VERSION "dbc-export 1 2026.26.6.5"

NS_ :

BS_:

BU_: APB APP APS DAS DPB EPAS3S EPASTS ESP GTW IBST IDB PARK RADC RCM RCM2 RCM3 RCU TPMS TRCM USM

BO_ 991 UI_status2: 8 GTW
 SG_ UI_mobileAppStepCount : 0|16@1+ (1,0) [0|65535] "" Vector__XXX
 SG_ UI_userRequestSnapshot : 16|1@1+ (1,0) [0|1] "" Vector__XXX
 SG_ UI_touchDetected : 17|1@1+ (1,0) [0|1] "" Vector__XXX
 SG_ UI_validDeviceForEUSummon : 18|1@1+ (1,0) [0|1] "" Vector__XXX
 SG_ UI_locatedAtHome : 19|1@1+ (1,0) [0|1] "" Vector__XXX
 SG_ UI_locatedAtWork : 20|1@1+ (1,0) [0|1] "" Vector__XXX
 SG_ UI_locatedAtFavorite : 21|1@1+ (1,0) [0|1] "" Vector__XXX
 SG_ UI_displayInDarkMode : 22|1@1+ (1,0) [0|1] "" Vector__XXX
 SG_ UI_userActivity : 23|1@1+ (1,0) [0|1] "" Vector__XXX
 SG_ UI_activeTouchPoints : 24|8@1+ (1,0) [0|255] "1" Vector__XXX
 SG_ UI_linkState : 32|2@1+ (1,0) [0|3] "" Vector__XXX
 SG_ UI_sentryModeState : 34|3@1+ (1,0) [0|7] "" Vector__XXX
 SG_ UI_autopilotSentryRequest : 37|1@1+ (1,0) [0|1] "" Vector__XXX
 SG_ UI_mobileAppConnected : 38|1@1+ (1,0) [0|1] "" Vector__XXX
 SG_ UI_phoneLeftInCabin : 39|1@1+ (1,0) [0|1] "" Vector__XXX
 SG_ UI_autoshiftDRState : 40|3@1+ (1,0) [0|7] "" Vector__XXX
 SG_ UI_wifiBtModuleType : 43|3@1+ (1,0) [0|7] "" Vector__XXX
 SG_ UI_sohHealthStatus : 46|2@1+ (1,0) [0|3] "" Vector__XXX
 SG_ UI_selfParkState : 48|8@1+ (1,0) [0|254] "" Vector__XXX
 SG_ UI_summonDeviceIndex : 56|2@1+ (1,0) [0|3] "" Vector__XXX
 SG_ UI_fullScreenMode : 58|1@1+ (1,0) [0|1] "" Vector__XXX
 SG_ UI_sentryModeCameraDetection : 59|1@1+ (1,0) [0|1] "" Vector__XXX
 SG_ UI_wakeOnIPActive : 60|1@1+ (1,0) [0|1] "" Vector__XXX
 SG_ UI_sapActive : 61|1@1+ (1,0) [0|1] "" Vector__XXX
 SG_ UI_sapClients : 62|1@1+ (1,0) [0|1] "" Vector__XXX
 SG_ UI_connectivityStandbyActive : 63|1@1+ (1,0) [0|1] "" Vector__XXX

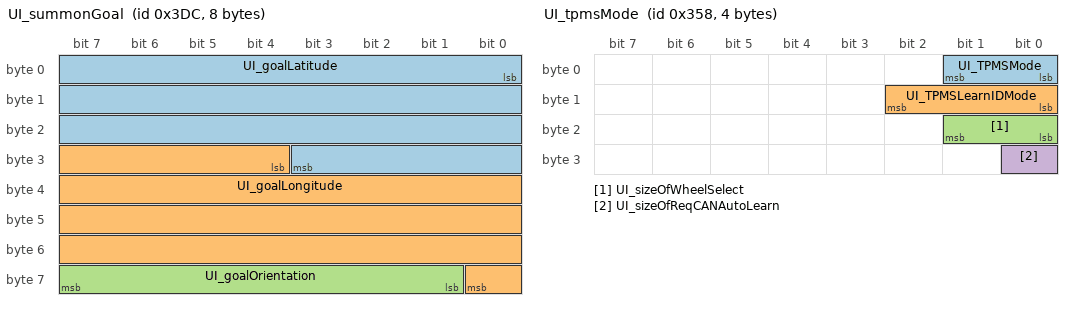
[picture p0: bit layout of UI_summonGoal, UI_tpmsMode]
BO_ 988 UI_summonGoal: 8 GTW
 SG_ UI_goalLatitude : 0|28@1- (1.0e-06,0) [-134.217728|134.217727] "deg" Vector__XXX
 SG_ UI_goalLongitude : 28|29@1- (1.0e-06,0) [-268.435456|268.435455] "deg" Vector__XXX
 SG_ UI_goalOrientation : 57|7@1+ (2.8125,0) [0|357.1875] "deg" Vector__XXX

BO_ 1064 UI_telemetryControl: 8 GTW
 SG_ UI_TCR_enable : 0|1@1+ (1,0) [0|1] "" Vector__XXX
 SG_ UI_TCR_moveStateStanding : 1|1@1+ (1,0) [0|1] "" Vector__XXX
 SG_ UI_TCR_moveStateStopped : 2|1@1+ (1,0) [0|1] "" Vector__XXX
 SG_ UI_TCR_moveStateMoving : 3|1@1+ (1,0) [0|1] "" Vector__XXX
 SG_ UI_TCR_moveStateIndeterm : 4|1@1+ (1,0) [0|1] "" Vector__XXX
 SG_ UI_TCR_classConstElem : 5|1@1+ (1,0) [0|1] "" Vector__XXX
 SG_ UI_TCR_classMovingPed : 6|1@1+ (1,0) [0|1] "" Vector__XXX
 SG_ UI_TCR_classMovingTwoWheel : 7|1@1+ (1,0) [0|1] "" Vector__XXX
 SG_ UI_TCR_classMovingFourWheel : 8|1@1+ (1,0) [0|1] "" Vector__XXX
 SG_ UI_TCR_classUnknown : 9|1@1+ (1,0) [0|1] "" Vector__XXX
 SG_ UI_TCR_downSampleFactor : 10|4@1+ (1,0) [0|15] "" Vector__XXX
 SG_ UI_TCR_wExist : 24|5@1+ (1,0) [0|31] "" Vector__XXX
 SG_ UI_TCR_vehSpeed : 32|8@1+ (1,0) [0|255] "" Vector__XXX
 SG_ UI_TCR_minRCS : 40|8@1+ (0.25,-14) [-14|49.75] "dB" Vector__XXX
 SG_ UI_TCR_maxDy : 48|5@1+ (0.5,0) [0|15.5] "m" Vector__XXX
 SG_ UI_TCR_maxObjects : 56|5@1+ (1,0) [0|31] "" Vector__XXX
 SG_ UI_TCR_maxRoadClass : 61|3@1+ (1,0) [0|7] "" Vector__XXX

BO_ 856 UI_tpmsMode: 4 GTW
 SG_ UI_TPMSMode : 0|2@1+ (1,0) [0|3] "" Vector__XXX
 SG_ UI_TPMSLearnIDMode : 8|3@1+ (1,0) [0|7] "" Vector__XXX
 SG_ UI_sizeOfWheelSelect : 16|2@1+ (1,0) [0|3] "" Vector__XXX
 SG_ UI_sizeOfReqCANAutoLearn : 24|1@1+ (1,0) [0|1] "" Vector__XXX

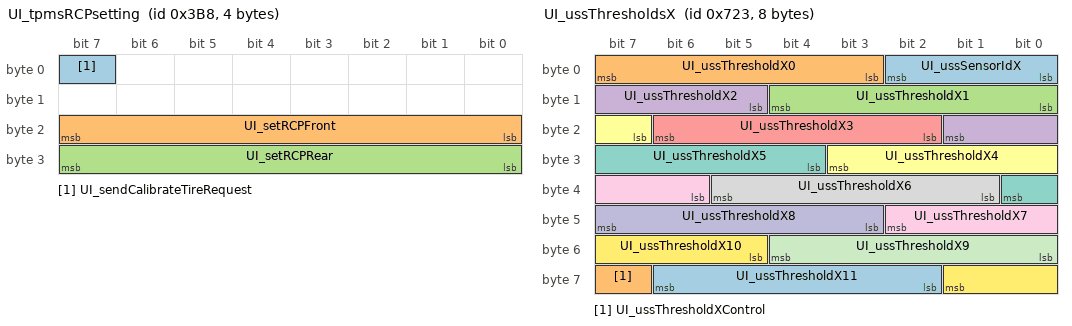
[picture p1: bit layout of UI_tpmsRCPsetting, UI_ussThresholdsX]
BO_ 952 UI_tpmsRCPsetting: 4 GTW
 SG_ UI_sendCalibrateTireRequest : 7|1@1+ (1,0) [0|1] "" Vector__XXX
 SG_ UI_setRCPFront : 16|8@1+ (0.025,0) [0|6.375] "bar" Vector__XXX
 SG_ UI_setRCPRear : 24|8@1+ (0.025,0) [0|6.375] "bar" Vector__XXX

BO_ 852 UI_uiHealthStatus: 6 GTW
 SG_ UI_centerDisplayRunning : 0|1@1+ (1,0) [0|1] "" Vector__XXX
 SG_ UI_centerDisplaySM : 1|3@1+ (1,0) [0|7] "" Vector__XXX
 SG_ UI_centerDisplayPowerOn : 4|1@1+ (1,0) [0|1] "" Vector__XXX
 SG_ UI_centerDisplayCrtcOk : 5|1@1+ (1,0) [0|1] "" Vector__XXX
 SG_ UI_centerDisplayHardwareOk : 6|1@1+ (1,0) [0|1] "" Vector__XXX
 SG_ UI_centerDisplayWindowManagerOk : 7|1@1+ (1,0) [0|1] "" Vector__XXX
 SG_ UI_centerDisplayCompositorOk : 8|1@1+ (1,0) [0|1] "" Vector__XXX
 SG_ UI_apVisualizationOk : 9|1@1+ (1,0) [0|1] "" Vector__XXX
 SG_ UI_autonomyCenterDispStatus : 10|2@1+ (1,0) [1|3] "" Vector__XXX
 SG_ UI_autonomyRearDispStatus : 12|2@1+ (1,0) [1|3] "" Vector__XXX
 SG_ UI_autonomyConnectivityStatus : 14|2@1+ (1,0) [1|3] "" Vector__XXX
 SG_ UI_autonomyConnectivtyHWOk : 16|1@1+ (1,0) [0|1] "" Vector__XXX
 SG_ UI_autonomyQtCarStatus : 17|2@1+ (1,0) [1|3] "" Vector__XXX
 SG_ UI_autonomyQtCarRearStatus : 19|2@1+ (1,0) [1|3] "" Vector__XXX
 SG_ UI_autonomyDASServerStatus : 21|2@1+ (1,0) [1|3] "" Vector__XXX
 SG_ UI_rearDisplayRunning : 23|1@1+ (1,0) [0|1] "" Vector__XXX
 SG_ UI_rearDisplayPowerOn : 24|1@1+ (1,0) [0|1] "" Vector__XXX
 SG_ UI_rearDisplaySM : 25|3@1+ (1,0) [0|7] "" Vector__XXX
 SG_ UI_rearDisplayCrtcOk : 28|1@1+ (1,0) [0|1] "" Vector__XXX
 SG_ UI_rearDisplayHardwareOk : 29|1@1+ (1,0) [0|1] "" Vector__XXX
 SG_ UI_rearDisplayWindowManagerOk : 30|1@1+ (1,0) [0|1] "" Vector__XXX
 SG_ UI_rearDisplayCompositorOk : 31|1@1+ (1,0) [0|1] "" Vector__XXX

BO_ 1827 UI_ussThresholdsX: 8 GTW
 SG_ UI_ussSensorIdX : 0|3@1+ (1,0) [0|7] "" Vector__XXX
 SG_ UI_ussThresholdX0 : 3|5@1+ (1,0) [0|31] "" Vector__XXX
 SG_ UI_ussThresholdX1 : 8|5@1+ (1,0) [0|31] "" Vector__XXX
 SG_ UI_ussThresholdX2 : 13|5@1+ (1,0) [0|31] "" Vector__XXX
 SG_ UI_ussThresholdX3 : 18|5@1+ (1,0) [0|31] "" Vector__XXX
 SG_ UI_ussThresholdX4 : 23|5@1+ (1,0) [0|31] "" Vector__XXX
 SG_ UI_ussThresholdX5 : 28|5@1+ (1,0) [0|31] "" Vector__XXX
 SG_ UI_ussThresholdX6 : 33|5@1+ (1,0) [0|31] "" Vector__XXX
 SG_ UI_ussThresholdX7 : 38|5@1+ (1,0) [0|31] "" Vector__XXX
 SG_ UI_ussThresholdX8 : 43|5@1+ (1,0) [0|31] "" Vector__XXX
 SG_ UI_ussThresholdX9 : 48|5@1+ (1,0) [0|31] "" Vector__XXX
 SG_ UI_ussThresholdX10 : 53|5@1+ (1,0) [0|31] "" Vector__XXX
 SG_ UI_ussThresholdX11 : 58|5@1+ (1,0) [0|31] "" Vector__XXX
 SG_ UI_ussThresholdXControl : 63|1@1+ (1,0) [0|1] "" Vector__XXX

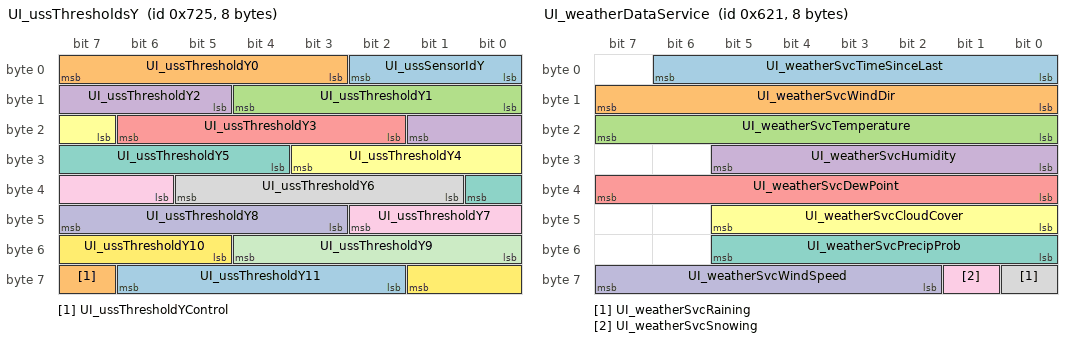
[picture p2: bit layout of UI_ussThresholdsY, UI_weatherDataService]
BO_ 1829 UI_ussThresholdsY: 8 GTW
 SG_ UI_ussSensorIdY : 0|3@1+ (1,0) [0|7] "" Vector__XXX
 SG_ UI_ussThresholdY0 : 3|5@1+ (1,0) [0|31] "" Vector__XXX
 SG_ UI_ussThresholdY1 : 8|5@1+ (1,0) [0|31] "" Vector__XXX
 SG_ UI_ussThresholdY2 : 13|5@1+ (1,0) [0|31] "" Vector__XXX
 SG_ UI_ussThresholdY3 : 18|5@1+ (1,0) [0|31] "" Vector__XXX
 SG_ UI_ussThresholdY4 : 23|5@1+ (1,0) [0|31] "" Vector__XXX
 SG_ UI_ussThresholdY5 : 28|5@1+ (1,0) [0|31] "" Vector__XXX
 SG_ UI_ussThresholdY6 : 33|5@1+ (1,0) [0|31] "" Vector__XXX
 SG_ UI_ussThresholdY7 : 38|5@1+ (1,0) [0|31] "" Vector__XXX
 SG_ UI_ussThresholdY8 : 43|5@1+ (1,0) [0|31] "" Vector__XXX
 SG_ UI_ussThresholdY9 : 48|5@1+ (1,0) [0|31] "" Vector__XXX
 SG_ UI_ussThresholdY10 : 53|5@1+ (1,0) [0|31] "" Vector__XXX
 SG_ UI_ussThresholdY11 : 58|5@1+ (1,0) [0|31] "" Vector__XXX
 SG_ UI_ussThresholdYControl : 63|1@1+ (1,0) [0|1] "" Vector__XXX

BO_ 947 UI_vehicleControl2: 8 GTW
 SG_ UI_gloveboxRequest : 0|1@1+ (1,0) [0|1] "" Vector__XXX
 SG_ UI_trunkRequest : 1|1@1+ (1,0) [0|1] "" Vector__XXX
 SG_ UI_UMCUpdateInhibit : 2|1@1+ (1,0) [0|1] "" Vector__XXX
 SG_ UI_WCUpdateInhibit : 3|1@1+ (1,0) [0|1] "" Vector__XXX
 SG_ UI_soundHornOnLock : 4|1@1+ (1,0) [0|1] "" Vector__XXX
 SG_ UI_locksPanelActive : 5|1@1+ (1,0) [0|1] "" Vector__XXX
 SG_ UI_PINToDriveEnabled : 6|1@1+ (1,0) [0|1] "" Vector__XXX
 SG_ UI_PINToDrivePassed : 7|1@1+ (1,0) [0|1] "" Vector__XXX
 SG_ UI_disableMirrorAutoDim : 8|1@1+ (1,0) [0|1] "" Vector__XXX
 SG_ UI_lightSwitch : 9|3@1+ (1,0) [0|7] "" Vector__XXX
 SG_ UI_readyToAddKey : 12|1@1+ (1,0) [0|1] "" Vector__XXX
 SG_ UI_alarmTriggerRequest : 13|1@1+ (1,0) [0|1] "" Vector__XXX
 SG_ UI_VCSECFeature1 : 14|1@1+ (1,0) [0|1] "" Vector__XXX
 SG_ UI_VCLEFTFeature1 : 15|1@1+ (1,0) [0|1] "" Vector__XXX
 SG_ UI_summonState : 16|2@1+ (1,0) [1|3] "" Vector__XXX
 SG_ UI_displayOnForUser : 18|1@1+ (1,0) [0|1] "" Vector__XXX
 SG_ UI_freeRollModeRequest : 19|1@1+ (1,0) [0|1] "" Vector__XXX
 SG_ UI_BLEPushNotificationRequest : 20|1@1+ (1,0) [0|1] "" Vector__XXX
 SG_ UI_pairKeyQRCodeDisplaying : 21|1@1+ (1,0) [0|1] "" Vector__XXX
 SG_ UI_keepAutopilotAwake : 22|1@1+ (1,0) [0|1] "" Vector__XXX
 SG_ UI_batteryPreconditioningRequest : 23|1@1+ (1,0) [0|1] "" Vector__XXX
 SG_ UI_coastDownMode : 24|1@1+ (1,0) [0|1] "" Vector__XXX
 SG_ UI_autopilotPowerStateRequest : 25|2@1+ (1,0) [0|3] "" Vector__XXX
 SG_ UI_shorted12VCellTestMode : 27|2@1+ (1,0) [0|3] "" Vector__XXX
 SG_ UI_autoRollWindowsOnLockEnable : 29|1@1+ (1,0) [0|1] "" Vector__XXX
 SG_ UI_virtualPitchSensorOverrideOKF : 30|1@1+ (1,0) [0|1] "" Vector__XXX
 SG_ UI_conditionalLoggingEnabledVCSE : 31|1@1+ (1,0) [0|1] "" Vector__XXX
 SG_ UI_WC3UpdateInhibit : 32|1@1+ (1,0) [0|1] "" Vector__XXX
 SG_ UI_steeringWheelHeatReq : 33|1@1+ (1,0) [0|1] "" Vector__XXX
 SG_ UI_disableHorn : 34|1@1+ (1,0) [0|1] "" Vector__XXX
 SG_ UI_frontLeftSeatFanReq : 37|2@1+ (1,0) [0|3] "" Vector__XXX
 SG_ UI_frontRightSeatAutoClimateReq : 39|1@1+ (1,0) [0|1] "" Vector__XXX
 SG_ UI_frontRightSeatFanReq : 40|2@1+ (1,0) [0|3] "" Vector__XXX
 SG_ UI_3RLeftSeatHeatReq : 44|2@1+ (1,0) [0|3] "" Vector__XXX
 SG_ UI_3RRightSeatHeatReq : 46|2@1+ (1,0) [0|3] "" Vector__XXX
 SG_ UI_sleepFeature1 : 51|1@1+ (1,0) [0|1] "" Vector__XXX
 SG_ UI_dcr12VThreshold : 52|4@1+ (1,0) [0|15] "" Vector__XXX
 SG_ UI_frontLeftSeatAutoClimateReq : 56|1@1+ (1,0) [0|1] "" Vector__XXX
 SG_ UI_wiperHeaterReq : 57|1@1+ (1,0) [0|1] "" Vector__XXX
 SG_ UI_tireSeason : 59|1@1+ (1,0) [0|1] "" Vector__XXX
 SG_ UI_saveTireConfigReq : 60|1@1+ (1,0) [0|1] "" Vector__XXX
 SG_ UI_silentAlarm : 61|1@1+ (1,0) [0|1] "" Vector__XXX
 SG_ UI_sleepFeature2 : 63|1@1+ (1,0) [0|1] "" Vector__XXX

BO_ 644 UI_vehicleModes: 8 GTW
 SG_ UI_factoryMode : 0|1@1+ (1,0) [0|1] "" Vector__XXX
 SG_ UI_transportMode : 1|1@1+ (1,0) [0|1] "" Vector__XXX
 SG_ UI_showroomMode : 2|1@1+ (1,0) [0|1] "" Vector__XXX
 SG_ UI_serviceMode : 3|1@1+ (1,0) [0|1] "" Vector__XXX
 SG_ UI_isDelivered : 4|1@1+ (1,0) [0|1] "" Vector__XXX
 SG_ UI_hasEverBeenDelivered : 5|1@1+ (1,0) [0|1] "" Vector__XXX
 SG_ UI_homelinkV2Command0 : 8|8@1+ (1,0) [0|255] "" Vector__XXX
 SG_ UI_homelinkV2Command1 : 16|8@1+ (1,0) [0|255] "" Vector__XXX
 SG_ UI_homelinkV2Command2 : 24|8@1+ (1,0) [0|255] "" Vector__XXX
 SG_ UI_carWashMode : 32|1@1+ (1,0) [0|1] "" Vector__XXX
 SG_ UI_valetMode : 33|1@1+ (1,0) [0|1] "" Vector__XXX
 SG_ UI_gameMode : 34|1@1+ (1,0) [0|1] "" Vector__XXX
 SG_ UI_diagnosticsAllowed : 35|1@1+ (1,0) [0|1] "" Vector__XXX
 SG_ UI_serviceModePlus : 36|1@1+ (1,0) [0|1] "" Vector__XXX
 SG_ UI_premiumAmpPowerOff : 37|1@1+ (1,0) [0|1] "" Vector__XXX
 SG_ UI_signedCmdHardLocked : 38|1@1+ (1,0) [0|1] "" Vector__XXX
 SG_ UI_signedCmdServiceMode : 39|1@1+ (1,0) [0|1] "" Vector__XXX
 SG_ UI_closureEasterEggStatus : 40|2@1+ (1,0) [0|3] "" Vector__XXX
 SG_ UI_lightShowType : 42|3@1+ (1,0) [0|7] "" Vector__XXX
 SG_ UI_sohTestRequest : 45|1@1+ (1,0) [0|1] "" Vector__XXX
 SG_ UI_upkeepMode : 46|1@1+ (1,0) [0|1] "" Vector__XXX
 SG_ UI_vehicleModesCounter : 52|4@1+ (1,0) [0|15] "" Vector__XXX
 SG_ UI_vehicleModesChecksum : 56|8@1+ (1,0) [0|255] "" Vector__XXX

BO_ 1569 UI_weatherDataService: 8 GTW
 SG_ UI_weatherSvcTimeSinceLast : 0|7@1+ (1,0) [0|126] "minutes" Vector__XXX
 SG_ UI_weatherSvcWindDir : 8|8@1+ (1.5,0) [0|381] "deg" Vector__XXX
 SG_ UI_weatherSvcTemperature : 16|8@1+ (0.5,-40) [-40|87] "degC" Vector__XXX
 SG_ UI_weatherSvcHumidity : 24|6@1+ (1.62,0) [0|100.44] "%" Vector__XXX
 SG_ UI_weatherSvcDewPoint : 32|8@1+ (0.5,-60) [-60|67] "degC" Vector__XXX
 SG_ UI_weatherSvcCloudCover : 40|6@1+ (1.62,0) [0|100.44] "%" Vector__XXX
 SG_ UI_weatherSvcPrecipProb : 48|6@1+ (1.62,0) [0|100.44] "%" Vector__XXX
 SG_ UI_weatherSvcRaining : 56|1@1+ (1,0) [0|1] "" Vector__XXX
 SG_ UI_weatherSvcSnowing : 57|1@1+ (1,0) [0|1] "" Vector__XXX
 SG_ UI_weatherSvcWindSpeed : 58|6@1+ (2,0) [0|124] "kph" Vector__XXX

BO_TX_BU_ 991 : GTW;
BO_TX_BU_ 988 : GTW;
BO_TX_BU_ 1064 : GTW;
BO_TX_BU_ 856 : GTW;
BO_TX_BU_ 952 : GTW;
BO_TX_BU_ 852 : GTW;
BO_TX_BU_ 1827 : GTW;
BO_TX_BU_ 1829 : GTW;
BO_TX_BU_ 947 : GTW;
BO_TX_BU_ 644 : GTW;
BO_TX_BU_ 1569 : GTW;
CM_ BO_ 991 "Touchscreen user interface computer message: status2; forwarded onto this bus by the gateway; frame length from the layout, not yet observed on a vehicle bus";
CM_ SG_ 991 UI_mobileAppStepCount "Touchscreen user interface computer: mobile app step count";
CM_ SG_ 991 UI_userRequestSnapshot "Touchscreen user interface computer: user request snapshot";
CM_ SG_ 991 UI_touchDetected "Touchscreen user interface computer: touch detected";
CM_ SG_ 991 UI_validDeviceForEUSummon "Touchscreen user interface computer: valid device for EU summon";
CM_ SG_ 991 UI_locatedAtHome "Touchscreen user interface computer: located at home";
CM_ SG_ 991 UI_locatedAtWork "Touchscreen user interface computer: located at work";
CM_ SG_ 991 UI_locatedAtFavorite "Touchscreen user interface computer: located at favorite";
CM_ SG_ 991 UI_displayInDarkMode "Touchscreen user interface computer: display in dark mode";
CM_ SG_ 991 UI_userActivity "Indicates user interaction with the center display";
CM_ SG_ 991 UI_activeTouchPoints "Quantity of active touch points on the Center Display";
CM_ SG_ 991 UI_linkState "Connectivity link state";
CM_ SG_ 991 UI_sentryModeState "Touchscreen user interface computer: sentry mode state; raw 6 = signal not available (SNA)";
CM_ SG_ 991 UI_autopilotSentryRequest "whether AP sentry mode should be enabled";
CM_ SG_ 991 UI_mobileAppConnected "Reports if Web Real-Time Communication (WebRTC) connection is connected while summon screen is open on the mobile app.";
CM_ SG_ 991 UI_phoneLeftInCabin "Used for monitoring phone left behind feature";
CM_ SG_ 991 UI_autoshiftDRState "Reports the User Interface (UI) autoshift Drive/Reverse state.";
CM_ SG_ 991 UI_wifiBtModuleType "Reports the type of Wi-Fi and Bluetooth (BT) module.";
CM_ SG_ 991 UI_sohHealthStatus "Touchscreen user interface computer: soh health status";
CM_ SG_ 991 UI_selfParkState "Reports the auto park state changes; raw 255 = signal not available (SNA)";
CM_ SG_ 991 UI_summonDeviceIndex "Reports which device is being used to control summon.";
CM_ SG_ 991 UI_fullScreenMode "Aggregates all situations with which the UI is using the entire screen so stalkless gear controls are not present";
CM_ SG_ 991 UI_sentryModeCameraDetection "Touchscreen user interface computer: sentry mode camera detection";
CM_ SG_ 991 UI_wakeOnIPActive "Touchscreen user interface computer: wake on IP active";
CM_ SG_ 991 UI_sapActive "Touchscreen user interface computer: sap active";
CM_ SG_ 991 UI_sapClients "Touchscreen user interface computer: sap clients";
CM_ SG_ 991 UI_connectivityStandbyActive "Touchscreen user interface computer: connectivity standby active";
CM_ BO_ 988 "Touchscreen user interface computer message: summon goal; forwarded onto this bus by the gateway; frame length from the layout, not yet observed on a vehicle bus";
CM_ SG_ 988 UI_goalLatitude "Touchscreen user interface computer: goal latitude";
CM_ SG_ 988 UI_goalLongitude "Touchscreen user interface computer: goal longitude";
CM_ SG_ 988 UI_goalOrientation "Touchscreen user interface computer: goal orientation";
CM_ BO_ 1064 "Touchscreen user interface computer message: telemetry control; forwarded onto this bus by the gateway; frame length from the layout, not yet observed on a vehicle bus";
CM_ SG_ 1064 UI_TCR_enable "Touchscreen user interface computer: TCR enable";
CM_ SG_ 1064 UI_TCR_moveStateStanding "Touchscreen user interface computer: TCR move state standing";
CM_ SG_ 1064 UI_TCR_moveStateStopped "Touchscreen user interface computer: TCR move state stopped";
CM_ SG_ 1064 UI_TCR_moveStateMoving "Touchscreen user interface computer: TCR move state moving";
CM_ SG_ 1064 UI_TCR_moveStateIndeterm "Touchscreen user interface computer: TCR move state indeterm";
CM_ SG_ 1064 UI_TCR_classConstElem "Touchscreen user interface computer: TCR class const elem";
CM_ SG_ 1064 UI_TCR_classMovingPed "Touchscreen user interface computer: TCR class moving ped";
CM_ SG_ 1064 UI_TCR_classMovingTwoWheel "Touchscreen user interface computer: TCR class moving two wheel";
CM_ SG_ 1064 UI_TCR_classMovingFourWheel "Touchscreen user interface computer: TCR class moving four wheel";
CM_ SG_ 1064 UI_TCR_classUnknown "Touchscreen user interface computer: TCR class unknown";
CM_ SG_ 1064 UI_TCR_downSampleFactor "Touchscreen user interface computer: TCR down sample factor";
CM_ SG_ 1064 UI_TCR_wExist "Touchscreen user interface computer: TCR w exist";
CM_ SG_ 1064 UI_TCR_vehSpeed "Touchscreen user interface computer: TCR veh speed";
CM_ SG_ 1064 UI_TCR_minRCS "Touchscreen user interface computer: TCR min RCS";
CM_ SG_ 1064 UI_TCR_maxDy "Touchscreen user interface computer: TCR max dy";
CM_ SG_ 1064 UI_TCR_maxObjects "Touchscreen user interface computer: TCR max objects";
CM_ SG_ 1064 UI_TCR_maxRoadClass "Touchscreen user interface computer: TCR max road class";
CM_ BO_ 856 "Touchscreen user interface computer message: tpms mode; forwarded onto this bus by the gateway; frame length from the layout, not yet observed on a vehicle bus";
CM_ SG_ 856 UI_TPMSMode "Touchscreen user interface computer: TPMS mode";
CM_ SG_ 856 UI_TPMSLearnIDMode "Touchscreen user interface computer: TPMS learn ID mode";
CM_ SG_ 856 UI_sizeOfWheelSelect "Touchscreen user interface computer: size of wheel select";
CM_ SG_ 856 UI_sizeOfReqCANAutoLearn "Touchscreen user interface computer: size of req CAN auto learn";
CM_ BO_ 952 "Touchscreen user interface computer message: tpms RC psetting; forwarded onto this bus by the gateway; frame length from the layout, not yet observed on a vehicle bus";
CM_ SG_ 952 UI_sendCalibrateTireRequest "Reports UI requests for PMDI to start the tire pressure calibration routine.";
CM_ SG_ 952 UI_setRCPFront "Touchscreen user interface computer: set RCP front";
CM_ SG_ 952 UI_setRCPRear "Touchscreen user interface computer: set RCP rear";
CM_ BO_ 852 "Touchscreen user interface computer message: ui health status; forwarded onto this bus by the gateway; frame length from the layout, not yet observed on a vehicle bus";
CM_ SG_ 852 UI_centerDisplayRunning "is center display running";
CM_ SG_ 852 UI_centerDisplaySM "Touchscreen user interface computer: center display SM";
CM_ SG_ 852 UI_centerDisplayPowerOn "center display power on";
CM_ SG_ 852 UI_centerDisplayCrtcOk "Touchscreen user interface computer: center display crtc ok";
CM_ SG_ 852 UI_centerDisplayHardwareOk "Touchscreen user interface computer: center display hardware ok";
CM_ SG_ 852 UI_centerDisplayWindowManagerOk "Touchscreen user interface computer: center display window manager ok";
CM_ SG_ 852 UI_centerDisplayCompositorOk "Touchscreen user interface computer: center display compositor ok";
CM_ SG_ 852 UI_apVisualizationOk "Touchscreen user interface computer: ap visualization ok";
CM_ SG_ 852 UI_autonomyCenterDispStatus "Touchscreen user interface computer: autonomy center disp status; raw 0 = signal not available (SNA)";
CM_ SG_ 852 UI_autonomyRearDispStatus "Touchscreen user interface computer: autonomy rear disp status; raw 0 = signal not available (SNA)";
CM_ SG_ 852 UI_autonomyConnectivityStatus "Touchscreen user interface computer: autonomy connectivity status; raw 0 = signal not available (SNA)";
CM_ SG_ 852 UI_autonomyConnectivtyHWOk "Touchscreen user interface computer: autonomy connectivty HW ok";
CM_ SG_ 852 UI_autonomyQtCarStatus "Signal reported by Touchscreen user interface computer; raw 0 = signal not available (SNA)";
CM_ SG_ 852 UI_autonomyQtCarRearStatus "Signal reported by Touchscreen user interface computer; raw 0 = signal not available (SNA)";
CM_ SG_ 852 UI_autonomyDASServerStatus "Touchscreen user interface computer: autonomy DAS server status; raw 0 = signal not available (SNA)";
CM_ SG_ 852 UI_rearDisplayRunning "is rear display running";
CM_ SG_ 852 UI_rearDisplayPowerOn "rear display power on";
CM_ SG_ 852 UI_rearDisplaySM "Touchscreen user interface computer: rear display SM";
CM_ SG_ 852 UI_rearDisplayCrtcOk "Touchscreen user interface computer: rear display crtc ok";
CM_ SG_ 852 UI_rearDisplayHardwareOk "Touchscreen user interface computer: rear display hardware ok";
CM_ SG_ 852 UI_rearDisplayWindowManagerOk "Touchscreen user interface computer: rear display window manager ok";
CM_ SG_ 852 UI_rearDisplayCompositorOk "Touchscreen user interface computer: rear display compositor ok";
CM_ BO_ 1827 "Touchscreen user interface computer message: uss thresholds x; forwarded onto this bus by the gateway; frame length from the layout, not yet observed on a vehicle bus";
CM_ SG_ 1827 UI_ussSensorIdX "Touchscreen user interface computer: uss sensor id x";
CM_ SG_ 1827 UI_ussThresholdX0 "Touchscreen user interface computer: uss threshold X0";
CM_ SG_ 1827 UI_ussThresholdX1 "Touchscreen user interface computer: uss threshold X1";
CM_ SG_ 1827 UI_ussThresholdX2 "Touchscreen user interface computer: uss threshold X2";
CM_ SG_ 1827 UI_ussThresholdX3 "Touchscreen user interface computer: uss threshold X3";
CM_ SG_ 1827 UI_ussThresholdX4 "Touchscreen user interface computer: uss threshold X4";
CM_ SG_ 1827 UI_ussThresholdX5 "Touchscreen user interface computer: uss threshold X5";
CM_ SG_ 1827 UI_ussThresholdX6 "Touchscreen user interface computer: uss threshold X6";
CM_ SG_ 1827 UI_ussThresholdX7 "Touchscreen user interface computer: uss threshold X7";
CM_ SG_ 1827 UI_ussThresholdX8 "Touchscreen user interface computer: uss threshold X8";
CM_ SG_ 1827 UI_ussThresholdX9 "Touchscreen user interface computer: uss threshold X9";
CM_ SG_ 1827 UI_ussThresholdX10 "Touchscreen user interface computer: uss threshold X10";
CM_ SG_ 1827 UI_ussThresholdX11 "Touchscreen user interface computer: uss threshold X11";
CM_ SG_ 1827 UI_ussThresholdXControl "Touchscreen user interface computer: uss threshold x control";
CM_ BO_ 1829 "Touchscreen user interface computer message: uss thresholds y; forwarded onto this bus by the gateway; frame length from the layout, not yet observed on a vehicle bus";
CM_ SG_ 1829 UI_ussSensorIdY "Touchscreen user interface computer: uss sensor id y";
CM_ SG_ 1829 UI_ussThresholdY0 "Touchscreen user interface computer: uss threshold Y0";
CM_ SG_ 1829 UI_ussThresholdY1 "Touchscreen user interface computer: uss threshold Y1";
CM_ SG_ 1829 UI_ussThresholdY2 "Touchscreen user interface computer: uss threshold Y2";
CM_ SG_ 1829 UI_ussThresholdY3 "Touchscreen user interface computer: uss threshold Y3";
CM_ SG_ 1829 UI_ussThresholdY4 "Touchscreen user interface computer: uss threshold Y4";
CM_ SG_ 1829 UI_ussThresholdY5 "Touchscreen user interface computer: uss threshold Y5";
CM_ SG_ 1829 UI_ussThresholdY6 "Touchscreen user interface computer: uss threshold Y6";
CM_ SG_ 1829 UI_ussThresholdY7 "Touchscreen user interface computer: uss threshold Y7";
CM_ SG_ 1829 UI_ussThresholdY8 "Touchscreen user interface computer: uss threshold Y8";
CM_ SG_ 1829 UI_ussThresholdY9 "Touchscreen user interface computer: uss threshold Y9";
CM_ SG_ 1829 UI_ussThresholdY10 "Touchscreen user interface computer: uss threshold Y10";
CM_ SG_ 1829 UI_ussThresholdY11 "Touchscreen user interface computer: uss threshold Y11";
CM_ SG_ 1829 UI_ussThresholdYControl "Touchscreen user interface computer: uss threshold y control";
CM_ BO_ 947 "Touchscreen user interface computer message: vehicle control2; forwarded onto this bus by the gateway; frame length from the layout, not yet observed on a vehicle bus";
CM_ SG_ 947 UI_gloveboxRequest "UI request to open the glovebox";
CM_ SG_ 947 UI_trunkRequest "Rear trunk request";
CM_ SG_ 947 UI_UMCUpdateInhibit "Touchscreen user interface computer: UMC update inhibit";
CM_ SG_ 947 UI_WCUpdateInhibit "Touchscreen user interface computer: WC update inhibit";
CM_ SG_ 947 UI_soundHornOnLock "Touchscreen user interface computer: sound horn on lock";
CM_ SG_ 947 UI_locksPanelActive "Touchscreen user interface computer: locks panel active";
CM_ SG_ 947 UI_PINToDriveEnabled "UI customer level request to pin to drive enabled.";
CM_ SG_ 947 UI_PINToDrivePassed "UI customer level request to enable drive with pin passed.";
CM_ SG_ 947 UI_disableMirrorAutoDim "Request to disable side and rear-view mirror auto dim";
CM_ SG_ 947 UI_lightSwitch "Headlight mode; raw 4 = signal not available (SNA)";
CM_ SG_ 947 UI_readyToAddKey "Ready to add key";
CM_ SG_ 947 UI_alarmTriggerRequest "Alarm activation request from UI";
CM_ SG_ 947 UI_VCSECFeature1 "Touchscreen user interface computer: VCSEC feature1";
CM_ SG_ 947 UI_VCLEFTFeature1 "Touchscreen user interface computer: VCLEFT feature1";
CM_ SG_ 947 UI_summonState "Touchscreen user interface computer: summon state; raw 0 = signal not available (SNA)";
CM_ SG_ 947 UI_displayOnForUser "User is present";
CM_ SG_ 947 UI_freeRollModeRequest "Touchscreen user interface computer: free roll mode request";
CM_ SG_ 947 UI_BLEPushNotificationRequest "Reports that the User Interface (UI) wants to talk to a phone and Vehicle Controller Security (VCSEC) should let all connected phones know.";
CM_ SG_ 947 UI_pairKeyQRCodeDisplaying "Touchscreen user interface computer: pair key QR code displaying";
CM_ SG_ 947 UI_keepAutopilotAwake "Reports the request for Vehicle Controller (VC) to keep autopilot awake.";
CM_ SG_ 947 UI_batteryPreconditioningRequest "Requests battery preconditioning.";
CM_ SG_ 947 UI_coastDownMode "Touchscreen user interface computer: coast down mode";
CM_ SG_ 947 UI_autopilotPowerStateRequest "Requests different power states from autopilot ECU depending on feature usage.";
CM_ SG_ 947 UI_shorted12VCellTestMode "Touchscreen user interface computer: shorted12 v cell test mode";
CM_ SG_ 947 UI_autoRollWindowsOnLockEnable "UI customer level request to enable auto-roll windows on lock";
CM_ SG_ 947 UI_virtualPitchSensorOverrideOKF "Touchscreen user interface computer: virtual pitch sensor override OK for aim";
CM_ SG_ 947 UI_conditionalLoggingEnabledVCSE "Touchscreen user interface computer: conditional logging enabled VCSEC";
CM_ SG_ 947 UI_WC3UpdateInhibit "Touchscreen user interface computer: WC3 update inhibit";
CM_ SG_ 947 UI_steeringWheelHeatReq "Request to enable steering wheel heater";
CM_ SG_ 947 UI_disableHorn "Request to disable horn";
CM_ SG_ 947 UI_frontLeftSeatFanReq "Request for front left seat ventilation";
CM_ SG_ 947 UI_frontRightSeatAutoClimateReq "UI setting to enable auto seat heating and cooling for front right seat";
CM_ SG_ 947 UI_frontRightSeatFanReq "Request for front left seat ventilation";
CM_ SG_ 947 UI_3RLeftSeatHeatReq "UI request for third row left seat heater";
CM_ SG_ 947 UI_3RRightSeatHeatReq "UI request for third row right seat heater";
CM_ SG_ 947 UI_sleepFeature1 "Touchscreen user interface computer: sleep feature1";
CM_ SG_ 947 UI_dcr12VThreshold "Touchscreen user interface computer: dcr12 v threshold";
CM_ SG_ 947 UI_frontLeftSeatAutoClimateReq "UI setting to enable auto seat heating and cooling for front left seat";
CM_ SG_ 947 UI_wiperHeaterReq "UI request to enable the wiper heater";
CM_ SG_ 947 UI_tireSeason "Touchscreen user interface computer: tire season";
CM_ SG_ 947 UI_saveTireConfigReq "Touchscreen user interface computer: save tire config req";
CM_ SG_ 947 UI_silentAlarm "Signal indicating alarms should be silenced";
CM_ SG_ 947 UI_sleepFeature2 "Touchscreen user interface computer: sleep feature2";
CM_ BO_ 644 "Touchscreen user interface computer message: vehicle modes; forwarded onto this bus by the gateway; frame length from the layout, not yet observed on a vehicle bus";
CM_ SG_ 644 UI_factoryMode "Touchscreen user interface computer: factory mode";
CM_ SG_ 644 UI_transportMode "Reports UI Transport mode. Distinct from GTW transport mode.";
CM_ SG_ 644 UI_showroomMode "Reports UI showroom mode.";
CM_ SG_ 644 UI_serviceMode "Service diagnostics mode active";
CM_ SG_ 644 UI_isDelivered "Touchscreen user interface computer: is delivered";
CM_ SG_ 644 UI_hasEverBeenDelivered "Touchscreen user interface computer: has ever been delivered";
CM_ SG_ 644 UI_homelinkV2Command0 "Touchscreen user interface computer: homelink V2 command0";
CM_ SG_ 644 UI_homelinkV2Command1 "Touchscreen user interface computer: homelink V2 command1";
CM_ SG_ 644 UI_homelinkV2Command2 "Touchscreen user interface computer: homelink V2 command2";
CM_ SG_ 644 UI_carWashMode "Car Wash Mode";
CM_ SG_ 644 UI_valetMode "Touchscreen user interface computer: valet mode";
CM_ SG_ 644 UI_gameMode "Game mode";
CM_ SG_ 644 UI_diagnosticsAllowed "Touchscreen user interface computer: diagnostics allowed";
CM_ SG_ 644 UI_serviceModePlus "Extended service diagnostics mode active";
CM_ SG_ 644 UI_premiumAmpPowerOff "Premium amplifier power off request";
CM_ SG_ 644 UI_signedCmdHardLocked "Touchscreen user interface computer: signed cmd hard locked";
CM_ SG_ 644 UI_signedCmdServiceMode "Signal reported by Touchscreen user interface computer";
CM_ SG_ 644 UI_closureEasterEggStatus "Touchscreen user interface computer: closure easter egg status";
CM_ SG_ 644 UI_lightShowType "Type of the light show to be run";
CM_ SG_ 644 UI_sohTestRequest "Touchscreen user interface computer: soh test request";
CM_ SG_ 644 UI_upkeepMode "Reports UI Upkeep Mode state.";
CM_ SG_ 644 UI_vehicleModesCounter "Touchscreen user interface computer: vehicle modes counter";
CM_ SG_ 644 UI_vehicleModesChecksum "Touchscreen user interface computer: vehicle modes checksum";
CM_ BO_ 1569 "Touchscreen user interface computer message: weather data service; forwarded onto this bus by the gateway; frame length from the layout, not yet observed on a vehicle bus";
CM_ SG_ 1569 UI_weatherSvcTimeSinceLast "Touchscreen user interface computer: weather svc time since last; raw 127 = signal not available (SNA)";
CM_ SG_ 1569 UI_weatherSvcWindDir "Touchscreen user interface computer: weather svc wind dir; raw 255 = signal not available (SNA)";
CM_ SG_ 1569 UI_weatherSvcTemperature "Touchscreen user interface computer: weather svc temperature; raw 255 = signal not available (SNA)";
CM_ SG_ 1569 UI_weatherSvcHumidity "Touchscreen user interface computer: weather svc humidity; raw 63 = signal not available (SNA)";
CM_ SG_ 1569 UI_weatherSvcDewPoint "Touchscreen user interface computer: weather svc dew point; raw 255 = signal not available (SNA)";
CM_ SG_ 1569 UI_weatherSvcCloudCover "Touchscreen user interface computer: weather svc cloud cover; raw 63 = signal not available (SNA)";
CM_ SG_ 1569 UI_weatherSvcPrecipProb "Touchscreen user interface computer: weather svc precip prob; raw 63 = signal not available (SNA)";
CM_ SG_ 1569 UI_weatherSvcRaining "Touchscreen user interface computer: weather svc raining";
CM_ SG_ 1569 UI_weatherSvcSnowing "Touchscreen user interface computer: weather svc snowing";
CM_ SG_ 1569 UI_weatherSvcWindSpeed "Touchscreen user interface computer: weather svc wind speed; raw 63 = signal not available (SNA)";
BA_DEF_ BO_ "GenMsgCycleTime" INT 0 3600000;
BA_DEF_ BO_ "GenMsgSendType" ENUM "Cyclic","NotUsed","NotUsed","NotUsed","NotUsed","NotUsed","NotUsed","IfActive","NoMsgSendType","NotUsed";
BA_DEF_ BO_ "VFrameFormat" ENUM "StandardCAN","ExtendedCAN","reserved","J1939PG","reserved","reserved","reserved","reserved","reserved","reserved","reserved","reserved","reserved","reserved","StandardCAN_FD","ExtendedCAN_FD";
BA_DEF_ BO_ "CANFD_BRS" ENUM "0","1";
BA_DEF_ SG_ "GenSigSNA" STRING;
BA_DEF_ SG_ "SystemSignalLongSymbol" STRING;
BA_DEF_ SG_ "Confidence" ENUM "validated","plausible","layout-only","contradicted";
BA_DEF_DEF_ "GenMsgCycleTime" 0;
BA_DEF_DEF_ "GenMsgSendType" "NoMsgSendType";
BA_DEF_DEF_ "VFrameFormat" "StandardCAN";
BA_DEF_DEF_ "CANFD_BRS" "1";
BA_DEF_DEF_ "GenSigSNA" "";
BA_DEF_DEF_ "SystemSignalLongSymbol" "";
BA_DEF_DEF_ "Confidence" "layout-only";
BA_ "GenMsgCycleTime" BO_ 991 500;
BA_ "GenMsgSendType" BO_ 991 0;
BA_ "GenMsgCycleTime" BO_ 988 1000;
BA_ "GenMsgSendType" BO_ 988 0;
BA_ "GenMsgCycleTime" BO_ 1064 1000;
BA_ "GenMsgSendType" BO_ 1064 0;
BA_ "GenMsgCycleTime" BO_ 952 1000;
BA_ "GenMsgSendType" BO_ 952 0;
BA_ "GenMsgCycleTime" BO_ 852 500;
BA_ "GenMsgSendType" BO_ 852 0;
BA_ "GenMsgCycleTime" BO_ 947 500;
BA_ "GenMsgSendType" BO_ 947 0;
BA_ "GenMsgCycleTime" BO_ 644 500;
BA_ "GenMsgSendType" BO_ 644 0;
BA_ "GenMsgCycleTime" BO_ 1569 500;
BA_ "GenMsgSendType" BO_ 1569 0;
BA_ "Confidence" SG_ 991 UI_mobileAppStepCount 1;
BA_ "Confidence" SG_ 991 UI_userRequestSnapshot 1;
BA_ "Confidence" SG_ 991 UI_touchDetected 1;
BA_ "Confidence" SG_ 991 UI_validDeviceForEUSummon 1;
BA_ "Confidence" SG_ 991 UI_locatedAtHome 1;
BA_ "Confidence" SG_ 991 UI_locatedAtWork 1;
BA_ "Confidence" SG_ 991 UI_locatedAtFavorite 1;
BA_ "Confidence" SG_ 991 UI_displayInDarkMode 1;
BA_ "Confidence" SG_ 991 UI_userActivity 0;
BA_ "Confidence" SG_ 991 UI_activeTouchPoints 0;
BA_ "Confidence" SG_ 991 UI_linkState 0;
BA_ "Confidence" SG_ 991 UI_sentryModeState 1;
BA_ "GenSigSNA" SG_ 991 UI_sentryModeState "6";
BA_ "Confidence" SG_ 991 UI_autopilotSentryRequest 0;
BA_ "Confidence" SG_ 991 UI_mobileAppConnected 0;
BA_ "Confidence" SG_ 991 UI_phoneLeftInCabin 0;
BA_ "Confidence" SG_ 991 UI_autoshiftDRState 0;
BA_ "Confidence" SG_ 991 UI_wifiBtModuleType 0;
BA_ "Confidence" SG_ 991 UI_sohHealthStatus 1;
BA_ "Confidence" SG_ 991 UI_selfParkState 0;
BA_ "GenSigSNA" SG_ 991 UI_selfParkState "255";
BA_ "Confidence" SG_ 991 UI_summonDeviceIndex 0;
BA_ "Confidence" SG_ 991 UI_fullScreenMode 0;
BA_ "Confidence" SG_ 991 UI_sentryModeCameraDetection 1;
BA_ "Confidence" SG_ 991 UI_wakeOnIPActive 1;
BA_ "Confidence" SG_ 991 UI_sapActive 1;
BA_ "Confidence" SG_ 991 UI_sapClients 1;
BA_ "Confidence" SG_ 991 UI_connectivityStandbyActive 1;
BA_ "Confidence" SG_ 988 UI_goalLatitude 1;
BA_ "Confidence" SG_ 988 UI_goalLongitude 1;
BA_ "Confidence" SG_ 988 UI_goalOrientation 1;
BA_ "Confidence" SG_ 1064 UI_TCR_minRCS 1;
BA_ "Confidence" SG_ 1064 UI_TCR_maxDy 1;
BA_ "Confidence" SG_ 856 UI_TPMSMode 1;
BA_ "Confidence" SG_ 856 UI_TPMSLearnIDMode 1;
BA_ "Confidence" SG_ 856 UI_sizeOfWheelSelect 1;
BA_ "Confidence" SG_ 952 UI_sendCalibrateTireRequest 0;
BA_ "Confidence" SG_ 952 UI_setRCPFront 0;
BA_ "Confidence" SG_ 952 UI_setRCPRear 0;
BA_ "Confidence" SG_ 852 UI_centerDisplayRunning 1;
BA_ "Confidence" SG_ 852 UI_centerDisplaySM 1;
BA_ "Confidence" SG_ 852 UI_centerDisplayPowerOn 1;
BA_ "Confidence" SG_ 852 UI_autonomyCenterDispStatus 1;
BA_ "GenSigSNA" SG_ 852 UI_autonomyCenterDispStatus "0";
BA_ "Confidence" SG_ 852 UI_autonomyRearDispStatus 1;
BA_ "GenSigSNA" SG_ 852 UI_autonomyRearDispStatus "0";
BA_ "Confidence" SG_ 852 UI_autonomyConnectivityStatus 1;
BA_ "GenSigSNA" SG_ 852 UI_autonomyConnectivityStatus "0";
BA_ "Confidence" SG_ 852 UI_autonomyQtCarStatus 1;
BA_ "GenSigSNA" SG_ 852 UI_autonomyQtCarStatus "0";
BA_ "Confidence" SG_ 852 UI_autonomyQtCarRearStatus 1;
BA_ "GenSigSNA" SG_ 852 UI_autonomyQtCarRearStatus "0";
BA_ "Confidence" SG_ 852 UI_autonomyDASServerStatus 1;
BA_ "GenSigSNA" SG_ 852 UI_autonomyDASServerStatus "0";
BA_ "Confidence" SG_ 852 UI_rearDisplayRunning 1;
BA_ "Confidence" SG_ 852 UI_rearDisplayPowerOn 1;
BA_ "Confidence" SG_ 852 UI_rearDisplaySM 1;
BA_ "Confidence" SG_ 1827 UI_ussSensorIdX 1;
BA_ "Confidence" SG_ 1829 UI_ussSensorIdY 1;
BA_ "Confidence" SG_ 947 UI_gloveboxRequest 0;
BA_ "Confidence" SG_ 947 UI_trunkRequest 0;
BA_ "Confidence" SG_ 947 UI_UMCUpdateInhibit 1;
BA_ "Confidence" SG_ 947 UI_WCUpdateInhibit 1;
BA_ "Confidence" SG_ 947 UI_soundHornOnLock 1;
BA_ "Confidence" SG_ 947 UI_locksPanelActive 1;
BA_ "Confidence" SG_ 947 UI_PINToDriveEnabled 0;
BA_ "Confidence" SG_ 947 UI_PINToDrivePassed 0;
BA_ "Confidence" SG_ 947 UI_disableMirrorAutoDim 0;
BA_ "Confidence" SG_ 947 UI_lightSwitch 0;
BA_ "GenSigSNA" SG_ 947 UI_lightSwitch "4";
BA_ "Confidence" SG_ 947 UI_readyToAddKey 0;
BA_ "Confidence" SG_ 947 UI_alarmTriggerRequest 0;
BA_ "Confidence" SG_ 947 UI_VCSECFeature1 1;
BA_ "Confidence" SG_ 947 UI_VCLEFTFeature1 1;
BA_ "Confidence" SG_ 947 UI_summonState 1;
BA_ "GenSigSNA" SG_ 947 UI_summonState "0";
BA_ "Confidence" SG_ 947 UI_displayOnForUser 0;
BA_ "Confidence" SG_ 947 UI_freeRollModeRequest 1;
BA_ "Confidence" SG_ 947 UI_BLEPushNotificationRequest 0;
BA_ "Confidence" SG_ 947 UI_pairKeyQRCodeDisplaying 1;
BA_ "Confidence" SG_ 947 UI_keepAutopilotAwake 0;
BA_ "Confidence" SG_ 947 UI_batteryPreconditioningRequest 0;
BA_ "Confidence" SG_ 947 UI_coastDownMode 1;
BA_ "Confidence" SG_ 947 UI_autopilotPowerStateRequest 0;
BA_ "Confidence" SG_ 947 UI_shorted12VCellTestMode 1;
BA_ "Confidence" SG_ 947 UI_autoRollWindowsOnLockEnable 0;
BA_ "Confidence" SG_ 947 UI_virtualPitchSensorOverrideOKF 1;
BA_ "SystemSignalLongSymbol" SG_ 947 UI_virtualPitchSensorOverrideOKF "UI_virtualPitchSensorOverrideOKForAim";
BA_ "Confidence" SG_ 947 UI_conditionalLoggingEnabledVCSE 1;
BA_ "SystemSignalLongSymbol" SG_ 947 UI_conditionalLoggingEnabledVCSE "UI_conditionalLoggingEnabledVCSEC";
BA_ "Confidence" SG_ 947 UI_WC3UpdateInhibit 1;
BA_ "Confidence" SG_ 947 UI_steeringWheelHeatReq 0;
BA_ "Confidence" SG_ 947 UI_disableHorn 0;
BA_ "Confidence" SG_ 947 UI_frontLeftSeatFanReq 0;
BA_ "Confidence" SG_ 947 UI_frontRightSeatAutoClimateReq 0;
BA_ "Confidence" SG_ 947 UI_frontRightSeatFanReq 0;
BA_ "Confidence" SG_ 947 UI_3RLeftSeatHeatReq 0;
BA_ "Confidence" SG_ 947 UI_3RRightSeatHeatReq 0;
BA_ "Confidence" SG_ 947 UI_sleepFeature1 1;
BA_ "Confidence" SG_ 947 UI_dcr12VThreshold 1;
BA_ "Confidence" SG_ 947 UI_frontLeftSeatAutoClimateReq 0;
BA_ "Confidence" SG_ 947 UI_wiperHeaterReq 0;
BA_ "Confidence" SG_ 947 UI_tireSeason 1;
BA_ "Confidence" SG_ 947 UI_saveTireConfigReq 1;
BA_ "Confidence" SG_ 947 UI_silentAlarm 0;
BA_ "Confidence" SG_ 947 UI_sleepFeature2 1;
BA_ "Confidence" SG_ 644 UI_factoryMode 1;
BA_ "Confidence" SG_ 644 UI_transportMode 0;
BA_ "Confidence" SG_ 644 UI_showroomMode 0;
BA_ "Confidence" SG_ 644 UI_serviceMode 0;
BA_ "Confidence" SG_ 644 UI_isDelivered 1;
BA_ "Confidence" SG_ 644 UI_hasEverBeenDelivered 1;
BA_ "Confidence" SG_ 644 UI_homelinkV2Command0 1;
BA_ "Confidence" SG_ 644 UI_homelinkV2Command1 1;
BA_ "Confidence" SG_ 644 UI_homelinkV2Command2 1;
BA_ "Confidence" SG_ 644 UI_carWashMode 0;
BA_ "Confidence" SG_ 644 UI_valetMode 1;
BA_ "Confidence" SG_ 644 UI_gameMode 0;
BA_ "Confidence" SG_ 644 UI_diagnosticsAllowed 1;
BA_ "Confidence" SG_ 644 UI_serviceModePlus 0;
BA_ "Confidence" SG_ 644 UI_premiumAmpPowerOff 0;
BA_ "Confidence" SG_ 644 UI_signedCmdHardLocked 1;
BA_ "Confidence" SG_ 644 UI_signedCmdServiceMode 1;
BA_ "Confidence" SG_ 644 UI_closureEasterEggStatus 1;
BA_ "Confidence" SG_ 644 UI_lightShowType 0;
BA_ "Confidence" SG_ 644 UI_sohTestRequest 1;
BA_ "Confidence" SG_ 644 UI_upkeepMode 0;
BA_ "Confidence" SG_ 644 UI_vehicleModesCounter 0;
BA_ "Confidence" SG_ 644 UI_vehicleModesChecksum 0;
BA_ "Confidence" SG_ 1569 UI_weatherSvcTimeSinceLast 0;
BA_ "GenSigSNA" SG_ 1569 UI_weatherSvcTimeSinceLast "127";
BA_ "Confidence" SG_ 1569 UI_weatherSvcWindDir 1;
BA_ "GenSigSNA" SG_ 1569 UI_weatherSvcWindDir "255";
BA_ "Confidence" SG_ 1569 UI_weatherSvcTemperature 1;
BA_ "GenSigSNA" SG_ 1569 UI_weatherSvcTemperature "255";
BA_ "Confidence" SG_ 1569 UI_weatherSvcHumidity 1;
BA_ "GenSigSNA" SG_ 1569 UI_weatherSvcHumidity "63";
BA_ "Confidence" SG_ 1569 UI_weatherSvcDewPoint 1;
BA_ "GenSigSNA" SG_ 1569 UI_weatherSvcDewPoint "255";
BA_ "Confidence" SG_ 1569 UI_weatherSvcCloudCover 1;
BA_ "GenSigSNA" SG_ 1569 UI_weatherSvcCloudCover "63";
BA_ "Confidence" SG_ 1569 UI_weatherSvcPrecipProb 1;
BA_ "GenSigSNA" SG_ 1569 UI_weatherSvcPrecipProb "63";
BA_ "Confidence" SG_ 1569 UI_weatherSvcRaining 1;
BA_ "Confidence" SG_ 1569 UI_weatherSvcSnowing 1;
BA_ "Confidence" SG_ 1569 UI_weatherSvcWindSpeed 1;
BA_ "GenSigSNA" SG_ 1569 UI_weatherSvcWindSpeed "63";
VAL_ 991 UI_userActivity 1 "USER_ACTIVE" 0 "USER_IDLE" ;
VAL_ 991 UI_linkState 2 "LINK_STATE_WIFI" 1 "LINK_STATE_CELL" 0 "LINK_STATE_NONE" ;
VAL_ 991 UI_sentryModeState 6 "SNA" 5 "QUIET" 4 "PANIC" 3 "AWARE" 2 "ARMED" 1 "IDLE" 0 "OFF" ;
VAL_ 991 UI_mobileAppConnected 1 "CONNECTED" 0 "NOT_CONNECTED" ;
VAL_ 991 UI_autoshiftDRState 6 "AUTOSHIFT_DR_STATE_BRAKE_GEAR_SHIFT_CONFIRMED_D" 5 "AUTOSHIFT_DR_STATE_BRAKE_GEAR_SHIFT_CONFIRMED_R" 4 "AUTOSHIFT_DR_STATE_BRAKE_STEERING_AND_BRAKE_CONFIRMED" 3 "AUTOSHIFT_DR_STATE_ONLY_STEERING_CONFIRMED" 2 "AUTOSHIFT_DR_STATE_ONLY_BRAKE_CONFIRMED" 1 "AUTOSHIFT_DR_STATE_PROMPT_SHOWING_UNCONFIRMED" 0 "AUTOSHIFT_DR_STATE_INACTIVE" ;
VAL_ 991 UI_wifiBtModuleType 4 "ELEKTRA" 3 "TCU4G" 2 "BCM4359" 1 "QCA6595" 0 "UNKNOWN" ;
VAL_ 991 UI_sohHealthStatus 3 "OK" 2 "REDUCED" 1 "NO_INTERNET" 0 "UNKNOWN" ;
VAL_ 991 UI_selfParkState 255 "SNA" 52 "SELF_PARK_USER_PAUSED" 51 "SELF_PARK_REMOTE_PRE_ABORT" 50 "SELF_PARK_RESUME" 49 "SELF_PARK_PAUSE" 48 "SELF_PARK_DV_MISMATCH" 47 "SELF_PARK_DI_PANIC" 46 "SELF_PARK_POST_ACTIVE_FAILURE" 45 "SELF_PARK_POST_ACTIVE_SUCCESS" 44 "SELF_PARK_CANCEL_AUTO_SUMMON" 43 "SELF_PARK_REMOTE_ABORT" 42 "SELF_PARK_OBSTACLE_NOT_CLEARED" 41 "SELF_PARK_OBSTACLE_CLEARED" 40 "SELF_PARK_OPEN_GATE" 39 "SELF_PARK_ACTIVE" 38 "SELF_PARK_STARTED_REVERSE" 37 "SELF_PARK_STARTED_FORWARD" 36 "SELF_PARK_NOT_STARTED_TIMEOUT" 35 "SELF_PARK_PRIMED" 34 "SELF_PARK_PREPRIMED" 33 "SELF_PARK_TURN_ON_DRIVE_RAIL" 32 "SELF_PARK_DETECT_KEY_FOB" 31 "SELF_PARK_WAKE_UP_BUSES" 30 "SELF_PARK_CONNECTING_BLUETOOTH" 29 "SELF_PARK_UNAVAILABLE_CAR_WASH_MODE" 28 "SELF_PARK_UNAVAILABLE_CAR_ALARM" 27 "SELF_PARK_UNAVAILABLE_CRASH_STATE" 26 "SELF_PARK_UNAVAILABLE_DRAG_STRIP_MODE" 25 "SELF_PARK_UNAVAILABLE_TRACK_MODE" 24 "SELF_PARK_UNAVAILABLE_SERVICE_MODE" 23 "SELF_PARK_UNAVAILABLE_DOG_MODE" 22 "SELF_PARK_UNAVAILABLE_GAME_MODE" 21 "SELF_PARK_UNAVAILABLE_BLUETOOTH_CONNECT_TIMEOUT" 20 "SELF_PARK_UNAVAILABLE_WAKEUP_TIMEOUT" 19 "SELF_PARK_UNAVAILABLE_NO_BLUETOOTH_DEVICES_PAIRED" 18 "SELF_PARK_UNAVAILABLE_BRAKE_PRESSED" 17 "SELF_PARK_UNAVAILABLE_ROAD_GRADE" 16 "SELF_PARK_UNAVAILABLE_TRAILER_MODE" 15 "SELF_PARK_UNAVAILABLE_KEY_FOB_BATTERY_LOW" 14 "SELF_PARK_UNAVAILABLE_KEY_FOB_NOT_DETECTED" 13 "SELF_PARK_UNAVAILABLE_PARK_SENSOR_ISSUE" 12 "SELF_PARK_UNAVAILABLE_AUTOSTEER_NOT_ENABLED" 11 "SELF_PARK_UNAVAILABLE_LV_BUS_SUPPORT_ISSUE" 10 "SELF_PARK_UNAVAILABLE_ON_PUBLIC_ROAD" 9 "SELF_PARK_UNAVAILABLE_PARKED_TOO_LONG" 8 "SELF_PARK_UNAVAILABLE_DOOR_OPEN" 7 "SELF_PARK_UNAVAILABLE_TRUNK_OPEN" 6 "SELF_PARK_UNAVAILABLE_FRUNK_OPEN" 5 "SELF_PARK_UNAVAILABLE_PLUGGED_IN" 4 "SELF_PARK_UNAVAILABLE_NOT_PARKED" 3 "SELF_PARK_UNAVAILABLE" 2 "SELF_PARK_IDLE" 1 "SELF_PARK_DRIVING" 0 "SELF_PARK_DISABLED" ;
VAL_ 991 UI_summonDeviceIndex 3 "UNKNOWN" 2 "DEVICE_2" 1 "DEVICE_1" 0 "DEVICE_0" ;
VAL_ 856 UI_TPMSMode 2 "PERFORMANCE_MODE" 1 "NORMAL_MODE" 0 "UNUSED_MODE" ;
VAL_ 856 UI_TPMSLearnIDMode 4 "AUTO_LOCATION_ACTIVE_AFTER_PWR" 3 "AUTO_LEARN_ACTIVE_AFTER_PWR" 2 "AUTO_LOCATION_ACTIVE_BY_MANUAL" 1 "AUTO_LEARN_ACTIVE_BY_MANUAL" 0 "NO_ID_LEARN_FUNCTION" ;
VAL_ 856 UI_sizeOfWheelSelect 2 "19_INCH_WHEEL" 1 "18_INCH_WHEEL" 0 "UNUSED" ;
VAL_ 852 UI_centerDisplaySM 4 "DOWN" 3 "TIMING_OUT" 2 "STALLING" 1 "UP" 0 "START" ;
VAL_ 852 UI_autonomyCenterDispStatus 2 "UNAVAILABLE" 1 "AVAILABLE" 0 "SNA" ;
VAL_ 852 UI_autonomyRearDispStatus 2 "UNAVAILABLE" 1 "AVAILABLE" 0 "SNA" ;
VAL_ 852 UI_autonomyConnectivityStatus 2 "OFFLINE" 1 "ONLINE" 0 "SNA" ;
VAL_ 852 UI_autonomyQtCarStatus 2 "UNAVAILABLE" 1 "AVAILABLE" 0 "SNA" ;
VAL_ 852 UI_autonomyQtCarRearStatus 2 "UNAVAILABLE" 1 "AVAILABLE" 0 "SNA" ;
VAL_ 852 UI_autonomyDASServerStatus 2 "UNAVAILABLE" 1 "AVAILABLE" 0 "SNA" ;
VAL_ 852 UI_rearDisplaySM 4 "DOWN" 3 "TIMING_OUT" 2 "STALLING" 1 "UP" 0 "START" ;
VAL_ 1827 UI_ussSensorIdX 5 "FRONT_SIDE" 4 "FRONT_CORNER" 3 "FRONT_INNER" 2 "REAR_SIDE" 1 "REAR_CORNER" 0 "REAR_INNER" ;
VAL_ 1829 UI_ussSensorIdY 5 "FRONT_SIDE" 4 "FRONT_CORNER" 3 "FRONT_INNER" 2 "REAR_SIDE" 1 "REAR_CORNER" 0 "REAR_INNER" ;
VAL_ 947 UI_lightSwitch 4 "LIGHT_SWITCH_SNA" 3 "LIGHT_SWITCH_OFF" 2 "LIGHT_SWITCH_PARKING" 1 "LIGHT_SWITCH_ON" 0 "LIGHT_SWITCH_AUTO" ;
VAL_ 947 UI_summonState 3 "ACTIVE" 2 "PRE_PRIMED" 1 "IDLE" 0 "SNA" ;
VAL_ 947 UI_autopilotPowerStateRequest 2 "AUTOPILOT_SUSPEND" 1 "AUTOPILOT_SENTRY" 0 "AUTOPILOT_NOMINAL" ;
VAL_ 947 UI_shorted12VCellTestMode 2 "ACTIVE" 1 "SHADOW" 0 "DISABLED" ;
VAL_ 947 UI_frontLeftSeatFanReq 3 "FAN_REQUEST_LEVEL3" 2 "FAN_REQUEST_LEVEL2" 1 "FAN_REQUEST_LEVEL1" 0 "FAN_REQUEST_OFF" ;
VAL_ 947 UI_frontRightSeatFanReq 3 "FAN_REQUEST_LEVEL3" 2 "FAN_REQUEST_LEVEL2" 1 "FAN_REQUEST_LEVEL1" 0 "FAN_REQUEST_OFF" ;
VAL_ 947 UI_3RLeftSeatHeatReq 3 "HEATER_REQUEST_LEVEL3" 2 "HEATER_REQUEST_LEVEL2" 1 "HEATER_REQUEST_LEVEL1" 0 "HEATER_REQUEST_OFF" ;
VAL_ 947 UI_3RRightSeatHeatReq 3 "HEATER_REQUEST_LEVEL3" 2 "HEATER_REQUEST_LEVEL2" 1 "HEATER_REQUEST_LEVEL1" 0 "HEATER_REQUEST_OFF" ;
VAL_ 947 UI_dcr12VThreshold 12 "15_MILLIOHMS" 11 "16_MILLIOHMS" 10 "17_MILLIOHMS" 9 "18_MILLIOHMS" 8 "19_MILLIOHMS" 7 "20_MILLIOHMS" 6 "22_MILLIOHMS" 5 "24_MILLIOHMS" 4 "27_MILLIOHMS" 3 "30_MILLIOHMS" 2 "35_MILLIOHMS" 1 "40_MILLIOHMS" 0 "OFF" ;
VAL_ 947 UI_tireSeason 1 "WINTER" 0 "NON_WINTER" ;
VAL_ 947 UI_saveTireConfigReq 1 "TRUE" 0 "FALSE" ;
VAL_ 644 UI_factoryMode 1 "ENABLED" 0 "DISABLED" ;
VAL_ 644 UI_transportMode 1 "TRANSPORT_MODE_ENABLED" 0 "TRANSPORT_MODE_DISABLED" ;
VAL_ 644 UI_showroomMode 1 "SHOWROOM_MODE_ENABLED" 0 "SHOWROOM_MODE_DISABLED" ;
VAL_ 644 UI_serviceMode 1 "SERVICE_MODE_ENABLED" 0 "SERVICE_MODE_DISABLED" ;
VAL_ 644 UI_diagnosticsAllowed 1 "ALLOWED" 0 "NOT_ALLOWED" ;
VAL_ 644 UI_serviceModePlus 1 "SERVICE_MODE_PLUS_ENABLED" 0 "SERVICE_MODE_PLUS_DISABLED" ;
VAL_ 644 UI_signedCmdHardLocked 1 "ENABLED" 0 "DISABLED" ;
VAL_ 644 UI_signedCmdServiceMode 1 "ENABLED" 0 "DISABLED" ;
VAL_ 644 UI_closureEasterEggStatus 3 "PLAYING" 2 "PRIMED" 1 "PRIMED_REMOTE" 0 "IDLE" ;
VAL_ 644 UI_lightShowType 5 "LIGHT_SHOW_TYPE_STANDARD_CNY24" 4 "LIGHT_SHOW_TYPE_STANDARD_THE_ARRIVAL" 3 "LIGHT_SHOW_TYPE_STANDARD_CNY23" 2 "LIGHT_SHOW_TYPE_STANDARD_AULD_LANG_SYNE" 1 "LIGHT_SHOW_TYPE_STANDARD_CAROL_OF_THE_BELLS" 0 "LIGHT_SHOW_TYPE_CUSTOM_USB" ;
VAL_ 644 UI_upkeepMode 1 "UI_UPKEEPMODE_ENABLED" 0 "UI_UPKEEPMODE_DISABLED" ;
VAL_ 1569 UI_weatherSvcTimeSinceLast 127 "SNA" ;
VAL_ 1569 UI_weatherSvcWindDir 255 "SNA" 240 "MAX" 0 "MIN" ;
VAL_ 1569 UI_weatherSvcTemperature 255 "SNA" 250 "MAX" 0 "MIN" ;
VAL_ 1569 UI_weatherSvcHumidity 63 "SNA" 62 "MAX" 0 "MIN" ;
VAL_ 1569 UI_weatherSvcDewPoint 255 "SNA" 250 "MAX" 0 "MIN" ;
VAL_ 1569 UI_weatherSvcCloudCover 63 "SNA" 62 "MAX" 0 "MIN" ;
VAL_ 1569 UI_weatherSvcPrecipProb 63 "SNA" 62 "MAX" 0 "MIN" ;
VAL_ 1569 UI_weatherSvcWindSpeed 63 "SNA" 60 "MAX" 0 "MIN" ;
